# STM32WB06 register map
File version: 1.0
CPU: CM0+ r0p0, little endian, MPU, no FPU, 2 interrupt priority bits
Registers are 32-bit, read-write, reset 0x0 unless marked. A register's access mark holds for its fields unless they carry their own. Offsets are from the block's base; lines under a group give offsets from that group; [hi:lo] are bit positions; {n}, {i} and the like mark numbered series; 'fields as' and 'values as' point back to an identical list; <NAME> marks a mode.

## Memory map
0x200000C0 GLOBALSTATMACH size 0x1C
0x40000000 SYSTEM_CTRL size 0x40
0x40001000 FLASH_CTRL size 0x2000 — 4kb addressable space
0x40002000 TIM1 size 0x68
0x40003000 IWDG size 0x14
0x40004000 RTC size 0x58
0x41000000 I2C1 size 0x400 — I2C address block description
0x41001000 I2C2 size 0x400
0x41002000 SPI1 size 0x24
0x41003000 SPI2 size 0x24
0x41004000 USART size 0x400 — USART address block description
0x41005000 LPUART size 0x30
0x41006000 ADC size 0x400 — ADC address block description
0x41007000 SPI3 size 0x24 — SPI address block description
0x48000000 GPIOA size 0x400 — GPIOA address block description
0x48100000 GPIOB size 0x2C
0x48200000 CRC size 0x400 — CRC address block description
0x48300000 PKA size 0x1400
0x48400000 RCC size 0xA0
0x48500000 PWRC size 0xA0
0x48600000 RNG size 0x1000
0x48700000 DMA size 0xA4
0x48800000 DMAMUX size 0x20
0x60000000 BLUE size 0x1000
0x60001000 RADIO_CONTROL size 0x400
0x60001400 RRM size 0x100
0x60001500 RADIO size 0x300
0x60001800 WAKEUP size 0x400

## Interrupts
0 FLASH (FLASH_CTRL) — Non-volatile memory (flash) controller
1 RCC — Reset and Clock Controller
2 BATTERY (RCC) — PVD
3 I2C1 — I2C1 interrupt
4 I2C2 — I2C2 interrupt
5 SPI1 — SPI1 interrupt
6 SPI2 — SPI2 interrupt
7 SPI3 — SPI3 interrupt
8 USART — USART interrupt
9 LPUART — LPUART interrupt
10 TIM1 — TIM1 interrupt
11 RTC — RTC interrupt
12 ADC — ADC interrupt
13 PKA — PKA interrupt
15 GPIOA — GPIOA interrupt
16 GPIOB — GPIOB interrupt
17 DMA — DMA interrupt
18 BLE_TX_RX_IRQn (BLUE) — BLE Tx/Rx interrupt
20 RADIO_ERROR (RADIO) — RADIO Error interrupt
23 RADIO_CPU_WKUP (RADIO) — RADIO CPU Wakeup interrupt
24 RADIO_TXRX_WKUP (RADIO) — RADIO Wakeup interrupt
25 RADIO_TXRX_SEQ (RADIO) — RADIO RX/TX sequence interrupt
27 TIM17 (USART) — TIM16 interrupt

## CRC — CRC address block description
Base 0x48200000
0x00 DR reset 0xFFFFFFFF — CRC data register
  [31:0] DR — Data register bits This register is used to write new data to the CRC calculator. It holds the previous CRC calculation result when it is read. If the data size is less than 32 bits, the least significant bits are used to write/read the correct value.
0x00 DR8 8-bit reset 0xFF (alternate view of DR) — Data register - byte sized
  [7:0] DR8 — Data register bits
0x00 DR16 16-bit reset 0xFFFF (alternate view of DR) — Data register - half-word sized
  [15:0] DR16 — Data register bits
0x04 IDR — CRC independent data register
  [31:0] IDR — General-purpose 32-bit data register bits These bits can be used as a temporary storage location for four bytes. This register is not affected by CRC resets generated by the RESET bit in the CRC_CR register
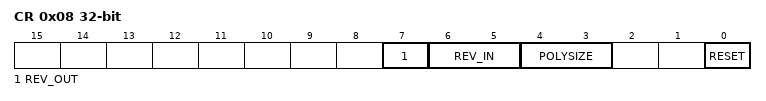
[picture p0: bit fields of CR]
0x08 CR — CRC control register
  [7] REV_OUT — Reverse output data This bit controls the reversal of the bit order of the output data.
    0=Normal (Bit order not affected); 1=Reversed (Bit reversed output)
  [6:5] REV_IN — Reverse input data This bitfield controls the reversal of the bit order of the input data
    0=Normal (Bit order not affected); 1=Byte (Bit reversal done by byte); 2=HalfWord (Bit reversal done by half-word); 3=Word (Bit reversal done by word)
  [4:3] POLYSIZE — Polynomial size These bits control the size of the polynomial.
    0=32-bit polynomial; 1=16-bit polynomial; 2=8-bit polynomial; 3=7-bit polynomial
  [0] RESET — RESET bit This bit is set by software to reset the CRC calculation unit and set the data register to the value stored in the CRC_INIT register. This bit can only be set, it is automatically cleared by hardware
    on write: 1=Resets the CRC calculation unit and sets the data register to 0xFFFF FFFF
0x10 INIT reset 0xFFFFFFFF — CRC initial value
  [31:0] INIT — Programmable initial CRC value This register is used to write the CRC initial value.
0x14 POL reset 0x4C11DB7 — CRC polynomial
  [31:0] POL — Programmable polynomial This register is used to write the coefficients of the polynomial to be used for CRC calculation. If the polynomial size is less than 32 bits, the least significant bits have to be used to program the correct value.
